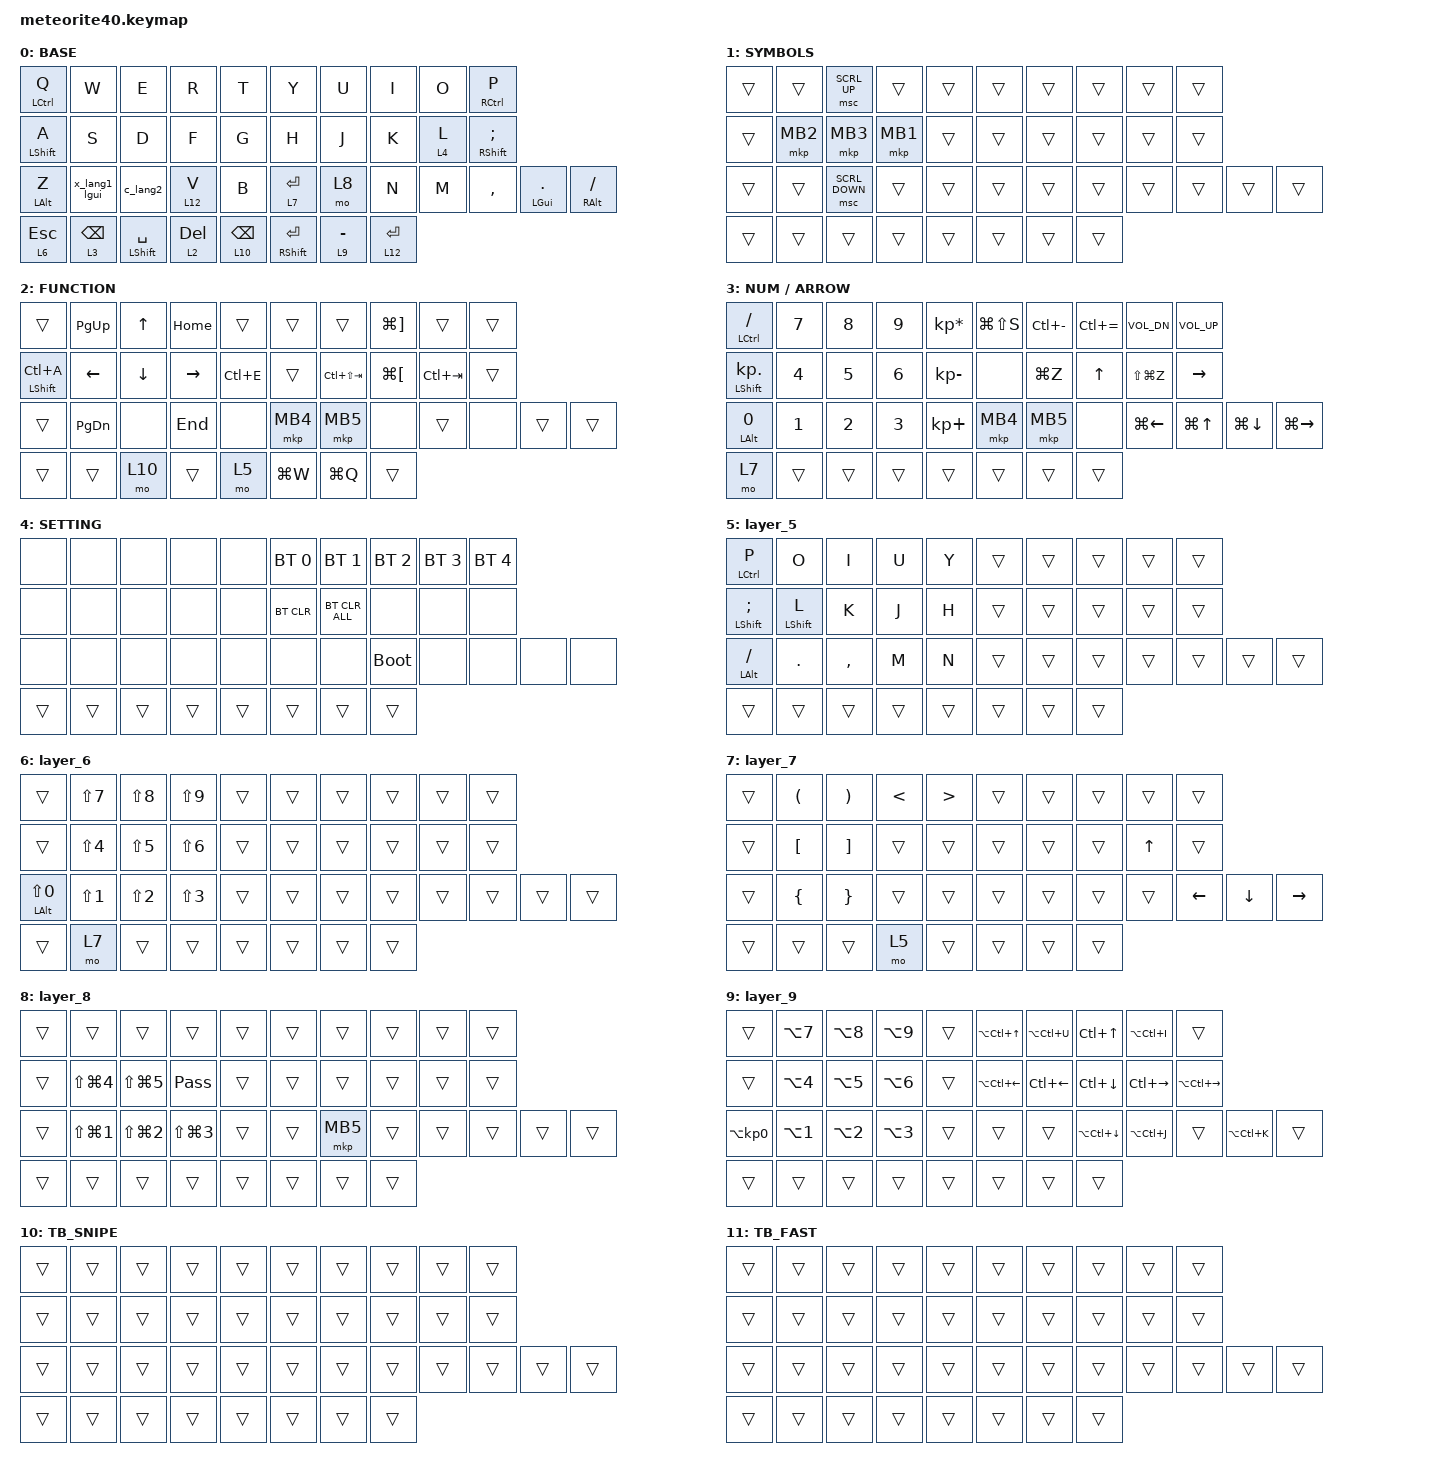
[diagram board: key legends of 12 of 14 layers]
#include <behaviors/custom_config.dtsi>
#include <dt-bindings/zmk/custom_config.h>

#define ZMK_POINTING_DEFAULT_SCRL_VAL 200

#include <input/processors.dtsi>
#include <behaviors.dtsi>
#include <dt-bindings/zmk/bt.h>
#include <dt-bindings/zmk/keys.h>
#include <dt-bindings/zmk/pointing.h>

&mkp_input_listener { input-processors = <&zip_temp_layer 1 1000>; };

&mmv_input_listener { input-processors = <&zip_temp_layer 1 1000>; };

&msc_input_listener { input-processors = <&zip_temp_layer 1 1000>; };

&zip_temp_layer { require-prior-idle-ms = <200>; };

&mt {
    flavor = "tap-preferred"; // change hold to tap
    tapping-term-ms = <200>;
    quick-tap-ms = <150>; // change 200 to 150
};

&lt {
    flavor = "tap-preferred";
    tapping-term-ms = <150>; // change 200 to 150
    quick-tap-ms = <150>; // change 200 to 150
};

/ {
    behaviors {
        mouse_scroll: mouse_wheel {
            compatible = "zmk,behavior-sensor-rotate-var";
            #sensor-binding-cells = <2>;
            bindings = <&msc>, <&msc>;

            tap-ms = <25>;
        };

        /* tap: X / double-tap: LANG1 / hold: LGUI */

        x_lang1_lgui: x_lang1_lgui {
            compatible = "zmk,behavior-tap-dance";
            #binding-cells = <0>;
            tapping-term-ms = <200>;
            bindings = <&mt RGUI X>, <&kp LANG1>;
        };

        /* tap: C / double-tap: LANG2 */

        c_lang2: c_lang2 {
            compatible = "zmk,behavior-tap-dance";
            #binding-cells = <0>;
            tapping-term-ms = <200>;
            bindings = <&kp C>, <&kp LANG2>;
        };
    };

    combos {
        compatible = "zmk,combos";

        lang1 {
            bindings = <&kp LG(C)>;
            key-positions = <21 22>; /* D + F */
            layers = <0>;
        };

        lang2 {
            bindings = <&kp LG(V)>;
            key-positions = <22 23>; /* J + K */
            layers = <0>;
        };

        esc {
            bindings = <&kp ESCAPE>;
            key-positions = <0 1>; /* Z + X */
            layers = <0>;
        };

        tab {
            bindings = <&kp TAB>;
            key-positions = <12 11>; /* Q + W */
            layers = <0>;
        };

        shift_tab {
            bindings = <&kp LS(TAB)>;
            key-positions = <13 12>;
        };

        cw {
            bindings = <&kp LG(W)>;
            key-positions = <16 17>;
        };

        cq {
            bindings = <&kp LG(Q)>;
            key-positions = <17 18>;
        };

        cut {
            bindings = <&kp LG(X)>;
            key-positions = <20 21>;
        };

        pastev {
            bindings = <&kp LA(LG(V))>;
            key-positions = <23 24>;
        };

        pdesk {
            bindings = <&kp LC(LEFT_ARROW)>;
            key-positions = <28 29>;
        };

        ndesk {
            bindings = <&kp LC(RIGHT_ARROW)>;
            key-positions = <29 30>;
        };

        upctrl {
            bindings = <&kp LC(UP_ARROW)>;
            key-positions = <29 17>;
        };

        downctrl {
            bindings = <&kp LC(DOWN_ARROW)>;
            key-positions = <29 39>;
        };

        enter {
            bindings = <&kp ENTER>;
            key-positions = <34 33>;
        };
    };

    macros {
        Pass: Pass {
            compatible = "zmk,behavior-macro";
            #binding-cells = <0>;
            bindings = <&none &kp N2 &kp N0 &kp N1 &kp N8 &kp N0 &kp N7 &kp N1 &kp N3 &kp LS(M) &kp A &kp C>;
            label = "PASS";
        };
    };

    keymap {
        compatible = "zmk,keymap";
        layout = &LAYOUT_2U_SPACE;

        win_default_layer {
            display-name = "BASE";
            bindings = <
&mt LCTRL Q     &kp W            &kp E            &kp R         &kp T             &kp Y            &kp U        &kp I         &kp O    &mt RCTRL P
&mt LSHFT A     &kp S            &kp D            &kp F         &kp G             &kp H            &kp J        &kp K         &lt 4 L  &mt RSHFT SEMICOLON
&mt LEFT_ALT Z  &x_lang1_lgui    &c_lang2         &lt 12 V      &kp B             &lt 7 ENTER      &mo 8        &kp N         &kp M    &kp COMMA            &mt LEFT_GUI PERIOD  &mt RIGHT_ALT SLASH
&lt 6 ESCAPE    &lt 3 BACKSPACE  &mt LSHFT SPACE  &lt 2 DELETE  &lt 10 BACKSPACE  &mt RSHFT ENTER  &lt 9 MINUS  &lt 12 ENTER
            >;

            sensor-bindings =
                <&inc_dec_kp LC(MINUS) LC(EQUAL)>,
                // RE0: ctrl + - / +,,,,,,,,,,,,,,,,,,,,,,,,,,,,,,,,,,,,,,,,,,,,,,,,,,,,,,,,,
                <&inc_dec_kp C_VOL_DN C_VOL_UP>;

            // RE1: volume down/up
            //<&mouse_scroll SCRL_LEFT SCRL_RIGHT>,
            //<&mouse_scroll SCRL_UP SCRL_DOWN>;
        };

        layer_1 {
            display-name = "SYMBOLS";
            bindings = <
&trans  &trans    &msc SCRL_UP    &trans    &trans  &trans  &trans  &trans  &trans  &trans
&trans  &mkp MB2  &mkp MB3        &mkp MB1  &trans  &trans  &trans  &trans  &trans  &trans
&trans  &trans    &msc SCRL_DOWN  &trans    &trans  &trans  &trans  &trans  &trans  &trans  &trans  &trans
&trans  &trans    &trans          &trans    &trans  &trans  &trans  &trans
            >;

            sensor-bindings =
                <&inc_dec_kp LC(MINUS) LC(EQUAL)>,
                // RE0: ctrl + - / +,,,,,,,,,,,,,,,,,,,,,,,,,,,,,,,,,,,,,,,,,,,,,,,,,,,,,,,,,
                <&inc_dec_kp C_VOL_DN C_VOL_UP>;

            // RE1: volume down/up
            //<&mouse_scroll SCRL_LEFT SCRL_RIGHT>,
            //<&mouse_scroll SCRL_UP SCRL_DOWN>;
        };

        layer_2 {
            display-name = "FUNCTION";
            bindings = <
&trans           &kp PAGE_UP     &kp UP_ARROW    &kp HOME         &trans     &trans     &trans           &kp LG(RIGHT_BRACKET)  &trans       &trans
&mt LSHFT LC(A)  &kp LEFT_ARROW  &kp DOWN_ARROW  &kp RIGHT_ARROW  &kp LC(E)  &trans     &kp LC(LS(TAB))  &kp LG(LEFT_BRACKET)   &kp LC(TAB)  &trans
&trans           &kp PAGE_DOWN   &none           &kp END          &none      &mkp MB4   &mkp MB5         &none                  &trans       &none   &trans  &trans
&trans           &trans          &mo 10          &trans           &mo 5      &kp LG(W)  &kp LG(Q)        &trans
            >;

            sensor-bindings =
                <&inc_dec_kp LC(MINUS) LC(EQUAL)>,
                // RE0: ctrl + - / +,,,,,,,,,,,,,,,,,,,,,,,,,,,,,,,,,,,,,,,,,,,,,,,,,,,,,,,,,
                <&inc_dec_kp C_VOL_DN C_VOL_UP>;

            // RE1: volume down/up
        };

        layer_3 {
            display-name = "NUM / ARROW";
            bindings = <
&mt LCTRL SLASH        &kp N7  &kp N8  &kp N9  &kp KP_MULTIPLY  &kp LG(LS(S))  &kp LC(MINUS)  &kp LC(EQUAL)  &kp C_VOL_DN   &kp C_VOL_UP
&mt LSHFT KP_DOT       &kp N4  &kp N5  &kp N6  &kp KP_MINUS     &none          &kp LG(Z)      &kp UP         &kp LS(LG(Z))  &kp RIGHT
&mt LEFT_ALT NUMBER_0  &kp N1  &kp N2  &kp N3  &kp KP_PLUS      &mkp MB4       &mkp MB5       &none          &kp LG(LEFT)   &kp LG(UP)    &kp LG(DOWN)  &kp LG(RIGHT)
&mo 7                  &trans  &trans  &trans  &trans           &trans         &trans         &trans
            >;

            sensor-bindings =
                <&inc_dec_kp LC(MINUS) LC(EQUAL)>,
                // RE0: ctrl + - / +,,,,,,,,,,,,,,,,,,,,,,,,,,,,,,,,,,,,,,,,,,,,,,,,,,,,,,,,,
                <&inc_dec_kp C_VOL_DN C_VOL_UP>;

            // RE1: volume down/up
        };

        layer_4 {
            display-name = "SETTING";
            bindings = <
&none   &none   &none   &none   &none   &bt BT_SEL 0  &bt BT_SEL 1    &bt BT_SEL 2  &bt BT_SEL 3  &bt BT_SEL 4
&none   &none   &none   &none   &none   &bt BT_CLR    &bt BT_CLR_ALL  &none         &none         &none
&none   &none   &none   &none   &none   &none         &none           &bootloader   &none         &none         &none  &none
&trans  &trans  &trans  &trans  &trans  &trans        &trans          &trans
            >;

            sensor-bindings =
                <&inc_dec_kp LC(MINUS) LC(EQUAL)>,
                // RE0: ctrl + - / +,,,,,,,,,,,,,,,,,,,,,,,,,,,,,,,,,,,,,,,,,,,,,,,,,,,,,,,,,
                <&inc_dec_kp C_VOL_DN C_VOL_UP>;

            // RE1: volume down/up
        };

        layer_5 {
            bindings = <
&mt LCTRL P          &kp O        &kp I      &kp U   &kp Y   &trans  &trans  &trans  &trans  &trans
&mt LSHFT SEMICOLON  &mt LSHFT L  &kp K      &kp J   &kp H   &trans  &trans  &trans  &trans  &trans
&mt LEFT_ALT SLASH   &kp DOT      &kp COMMA  &kp M   &kp N   &trans  &trans  &trans  &trans  &trans  &trans  &trans
&trans               &trans       &trans     &trans  &trans  &trans  &trans  &trans
            >;
        };

        layer_6 {
            bindings = <
&trans                     &kp LS(NUMBER_7)  &kp LS(NUMBER_8)  &kp LS(NUMBER_9)  &trans  &trans  &trans  &trans  &trans  &trans
&trans                     &kp LS(NUMBER_4)  &kp LS(NUMBER_5)  &kp LS(NUMBER_6)  &trans  &trans  &trans  &trans  &trans  &trans
&mt LEFT_ALT LS(NUMBER_0)  &kp LS(NUMBER_1)  &kp LS(NUMBER_2)  &kp LS(NUMBER_3)  &trans  &trans  &trans  &trans  &trans  &trans  &trans  &trans
&trans                     &mo 7             &trans            &trans            &trans  &trans  &trans  &trans
            >;
        };

        layer_7 {
            bindings = <
&trans  &kp LEFT_PARENTHESIS  &kp RIGHT_PARENTHESIS  &kp LESS_THAN  &kp GREATER_THAN  &trans  &trans  &trans  &trans  &trans
&trans  &kp LBKT              &kp RBKT               &trans         &trans            &trans  &trans  &trans  &kp UP  &trans
&trans  &kp LEFT_BRACE        &kp RIGHT_BRACE        &trans         &trans            &trans  &trans  &trans  &trans  &kp LEFT  &kp DOWN  &kp RIGHT
&trans  &trans                &trans                 &mo 5          &trans            &trans  &trans  &trans
            >;
        };

        layer_8 {
            bindings = <
&trans  &trans                &trans                &trans                &trans  &trans  &trans    &trans  &trans  &trans
&trans  &kp LS(LG(NUMBER_4))  &kp LS(LG(NUMBER_5))  &Pass                 &trans  &trans  &trans    &trans  &trans  &trans
&trans  &kp LS(LG(NUMBER_1))  &kp LS(LG(NUMBER_2))  &kp LS(LG(NUMBER_3))  &trans  &trans  &mkp MB5  &trans  &trans  &trans  &trans  &trans
&trans  &trans                &trans                &trans                &trans  &trans  &trans    &trans
            >;
        };

        layer_9 {
            bindings = <
&trans               &kp LA(N7)  &kp LA(N8)  &kp LA(N9)  &trans  &kp LA(LC(UP_ARROW))    &kp LA(LC(U))  &kp LC(UP)              &kp LA(LC(I))  &trans
&trans               &kp LA(N4)  &kp LA(N5)  &kp LA(N6)  &trans  &kp LA(LC(LEFT_ARROW))  &kp LC(LEFT)   &kp LC(DOWN)            &kp LC(RIGHT)  &kp LA(LC(RIGHT_ARROW))
&kp LA(KP_NUMBER_0)  &kp LA(N1)  &kp LA(N2)  &kp LA(N3)  &trans  &trans                  &trans         &kp LA(LC(DOWN_ARROW))  &kp LA(LC(J))  &trans                   &kp LA(LC(K))  &trans
&trans               &trans      &trans      &trans      &trans  &trans                  &trans         &trans
            >;
        };

        layer_10 {
            display-name = "TB_SNIPE"; /* 任意 */
            bindings = <
&trans  &trans  &trans  &trans  &trans  &trans  &trans  &trans  &trans  &trans
&trans  &trans  &trans  &trans  &trans  &trans  &trans  &trans  &trans  &trans
&trans  &trans  &trans  &trans  &trans  &trans  &trans  &trans  &trans  &trans  &trans  &trans
&trans  &trans  &trans  &trans  &trans  &trans  &trans  &trans
            >;
        };

        layer_11 {
            display-name = "TB_FAST";
            bindings = <
&trans  &trans  &trans  &trans  &trans  &trans  &trans  &trans  &trans  &trans
&trans  &trans  &trans  &trans  &trans  &trans  &trans  &trans  &trans  &trans
&trans  &trans  &trans  &trans  &trans  &trans  &trans  &trans  &trans  &trans  &trans  &trans
&trans  &trans  &trans  &trans  &trans  &trans  &trans  &trans
            >;
        };

        layer_12 {
            bindings = <
&trans       &trans           &trans           &trans  &trans  &trans  &trans  &trans  &trans  &trans
&trans       &trans           &trans           &trans  &trans  &trans  &trans  &trans  &kp UP  &trans
&bootloader  &kp LS(LC(F12))  &kp LS(LC(F11))  &trans  &trans  &trans  &trans  &trans  &trans  &kp LEFT  &kp DOWN  &kp RIGHT
&trans       &trans           &trans           &trans  &trans  &trans  &trans  &trans
            >;
        };

        layer_13 {
            bindings = <
&trans  &trans  &trans  &trans  &trans  &trans  &trans  &trans  &trans  &trans
&trans  &trans  &trans  &trans  &trans  &trans  &trans  &trans  &trans  &trans
&trans  &trans  &trans  &trans  &trans  &trans  &trans  &trans  &trans  &trans  &trans  &trans
&trans  &trans  &trans  &trans  &trans  &trans  &trans  &trans
            >;
        };
    };
};
